# NSS_0_CFG_INTD register map
Vendor: Texas Instruments
Peripheral module from a debugger description file (folder 66AK2G0x_66AK2G1x).
Registers are 32-bit, read-only, reset 0x0 unless marked. A register's access mark holds for its fields unless they carry their own. Offsets are as the file gives them; lines under a group give offsets from that group; [hi:lo] are bit positions; {n}, {i} and the like mark numbered series; 'fields as' and 'values as' point back to an identical list; <NAME> marks a mode.

## NSS_0_CFG_INTD
0x00 INTD_REVISION_REG reset 0x1E83A100
  [31:0] REV — TI internal data. Identifies revision of peripheral.
0x04 INTD_CONTROL_REG
0x10 INTD_EOI_REG access per field
  [7:0] EOI_VECTOR ro — End of Interrupt Vector
0x140 INTD_INTR_VECTOR_REG
  [31:0] INTR_VECTOR — Interrupt Vector Register. The register has the latest prioritized interrupt values.
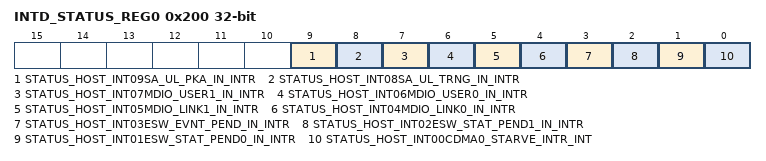
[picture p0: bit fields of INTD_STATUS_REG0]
0x200 INTD_STATUS_REG0 access not given
  [9] STATUS_HOST_INT09SA_UL_PKA_IN_INTR ro — Status for INT09SA_UL_PKA_IN_INTR
  [8] STATUS_HOST_INT08SA_UL_TRNG_IN_INTR ro — Status for INT08SA_UL_TRNG_IN_INTR
  [7] STATUS_HOST_INT07MDIO_USER1_IN_INTR ro — Status for INT07MDIO_USER1_IN_INTR
  [6] STATUS_HOST_INT06MDIO_USER0_IN_INTR ro — Status for INT06MDIO_USER0_IN_INTR
  [5] STATUS_HOST_INT05MDIO_LINK1_IN_INTR ro — Status for INT05MDIO_LINK1_IN_INTR
  [4] STATUS_HOST_INT04MDIO_LINK0_IN_INTR ro — Status for INT04MDIO_LINK0_IN_INTR
  [3] STATUS_HOST_INT03ESW_EVNT_PEND_IN_INTR ro — Status for INT03ESW_EVNT_PEND_IN_INTR
  [2] STATUS_HOST_INT02ESW_STAT_PEND1_IN_INTR ro — Status for INT02ESW_STAT_PEND1_IN_INTR
  [1] STATUS_HOST_INT01ESW_STAT_PEND0_IN_INTR ro — Status for INT01ESW_STAT_PEND0_IN_INTR
  [0] STATUS_HOST_INT00CDMA0_STARVE_INTR_INT — Status (write 1 to set) for INT00CDMA0_STARVE_INTR_INT (access W1TS)
0x280 INTD_STATUS_CLR_REG0 access not given
  [0] STATUS_HOST_INT00CDMA0_STARVE_INTR_INT_CLR — Status (write 1 to clear) for INT00CDMA0_STARVE_INTR_INT (access W1TC)
0x300 INTD_INTCNT_REG0
  [7:0] INTCNT_HOST_CNT_INT00CDMA0_STARVE_INTR_INT — Interrupt Count for HOST_CNT_INT00CDMA0_STARVE_INTR_INT (write to decrement)
0x480 INTD_INTR_VECTOR_REG_HOST
  [31:0] INTR_VECTOR_HOST — Interrupt Vector
